# LPC55S06 register map
Vendor: nxp.com; File version: 1.0
CPU: CM33 r2p0, little endian, MPU, FPU, VTOR, 3 interrupt priority bits
Registers are 32-bit, read-write, reset 0x0 unless marked. A register's access mark holds for its fields unless they carry their own. Offsets are from the block's base; [hi:lo] are bit positions; {n}, {i} and the like mark numbered series.

## UTICK0 — Micro-tick Timer (UTICK)
Base 0x4000E000
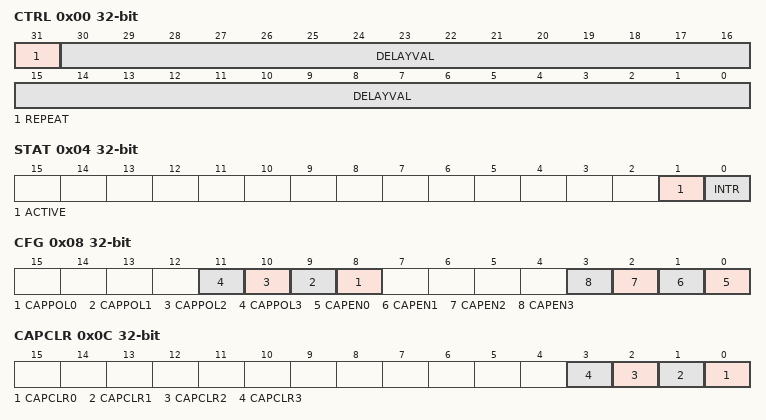
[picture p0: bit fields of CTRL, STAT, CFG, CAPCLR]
0x00 CTRL — Control register.
  [31] REPEAT — Repeat delay. 0 = One-time delay. 1 = Delay repeats continuously.
  [30:0] DELAYVAL — Tick interval value. The delay will be equal to DELAYVAL + 1 periods of the timer clock. The minimum usable value is 1, for a delay of 2 timer clocks. A value of 0 stops the timer.
0x04 STAT — Status register.
  [1] ACTIVE — Active flag. 0 = The Micro-Tick Timer is stopped. 1 = The Micro-Tick Timer is currently active.
  [0] INTR — Interrupt flag. 0 = No interrupt is pending. 1 = An interrupt is pending. A write of any value to this register clears this flag.
0x08 CFG — Capture configuration register.
  [n+8] CAPPOL{n} (n=0..3) — Capture Polarity {n}. 0 = Positive edge capture, 1 = Negative edge capture.
  [n] CAPEN{n} (n=0..3) — Enable Capture {n}. 1 = Enabled, 0 = Disabled.
0x0C CAPCLR wo reset not defined — Capture clear register.
  [n] CAPCLR{n} (n=0..3) — Clear capture {n}. Writing 1 to this bit clears the CAP{n} register value.
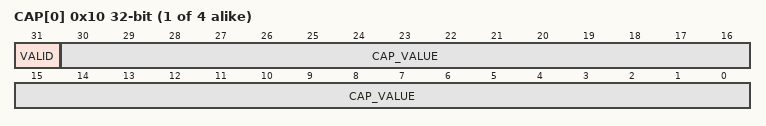
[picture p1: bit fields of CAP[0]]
{0x10+4i} CAP[{i}] (i=0..3) ro — Capture register .
  [31] VALID — Capture Valid. When 1, a value has been captured based on a transition of the related UTICK_CAPn pin. Cleared by writing to the related bit in the CAPCLR register.
  [30:0] CAP_VALUE — Capture value for the related capture event (UTICK_CAPn. Note: the value is 1 lower than the actual value of the Micro-tick Timer at the moment of the capture event.

## OSTIMER — Synchronous OS/Event timer with Wakeup Timer
Base 0x4002D000
0x00 EVTIMERL ro — EVTIMER Low Register
  [31:0] EVTIMER_COUNT_VALUE — A read reflects the current value of the lower 32 bits of the 42-bits EVTIMER. Note there is only one EVTIMER, readable from all domains.
0x04 EVTIMERH — EVTIMER High Register
  [9:0] EVTIMER_COUNT_VALUE ro — A read reflects the current value of the upper 10 bits of the 42-bits EVTIMER. Note there is only one EVTIMER, readable from all domains.
0x08 CAPTURE_L ro — Capture Low Register
  [31:0] CAPTURE_VALUE — A read reflects the value of the lower 32 bits of the central 42-bits EVTIMER at the time the last capture signal was generated by the CPU (using CMSIS C function "__SEV();").
0x0C CAPTURE_H — Capture High Register
  [9:0] CAPTURE_VALUE ro — A read reflects the value of the upper 10 bits of the central 42-bits EVTIMER at the time the last capture signal was generated by the CPU (using CMSIS C function "__SEV();").
0x10 MATCH_L reset 0xFFFFFFFF — Match Low Register
  [31:0] MATCH_VALUE — The value written to the MATCH (L/H) register pair is compared against the central EVTIMER. When a match occurs, an interrupt request is generated if enabled.
0x14 MATCH_H reset 0xFFFFFFFF — Match High Register
  [9:0] MATCH_VALUE — The value written (upper 10 bits) to the MATCH (L/H) register pair is compared against the central EVTIMER. When a match occurs, an interrupt request is generated if enabled.
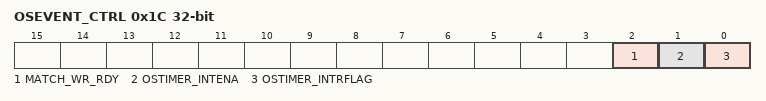
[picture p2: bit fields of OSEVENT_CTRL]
0x1C OSEVENT_CTRL — OS_EVENT TIMER Control Register
  [2] MATCH_WR_RDY ro — This bit will be low when it is safe to write to reload the Match Registers. In typical applications it should not be necessary to test this bit. [1]
  [1] OSTIMER_INTENA — When this bit is '1' an interrupt/wakeup request to the domain processor will be asserted when the OSTIMER_INTR flag is set. When this bit is '0', interrupt/wakeup requests due to the OSTIMER_INTR flag are blocked.
  [0] OSTIMER_INTRFLAG — This bit is set when a match occurs between the central 42-bits EVTIMER and the value programmed in the match-register pair. This bit is cleared by writing a '1'. Writes to clear this bit are asynchronous. It should be done before a new match value is written into the MATCH_L/H registers.
